AUTOSAR XML (schema 4-0-3)
package /ComponentTypes
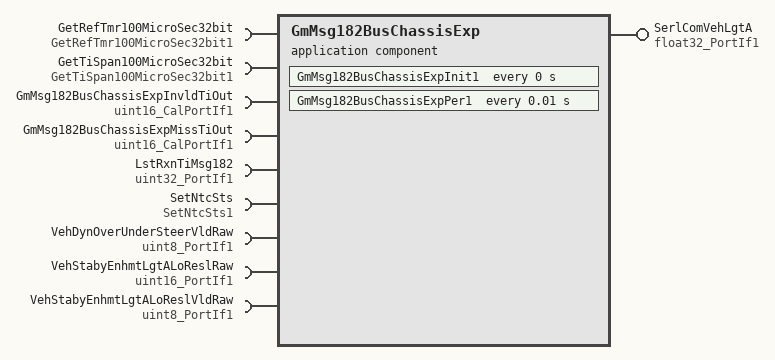
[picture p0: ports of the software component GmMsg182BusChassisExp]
  application sw component type GmMsg182BusChassisExp
    provide port SerlComVehLgtA: nonqueued-sender-com-spec{data-element=Val, init-value=0}, provided-interface=float32_PortIf1
    9 x require port:
      GetRefTmr100MicroSec32bit: required-interface=GetRefTmr100MicroSec32bit1
      GetTiSpan100MicroSec32bit: required-interface=GetTiSpan100MicroSec32bit1
      GmMsg182BusChassisExpInvldTiOut: parameter-require-com-spec{init-value=500, parameter=Val}, required-interface=uint16_CalPortIf1
      GmMsg182BusChassisExpMissTiOut: parameter-require-com-spec{init-value=1000, parameter=Val}, required-interface=uint16_CalPortIf1
      LstRxnTiMsg182: nonqueued-receiver-com-spec{data-element=Val, filter=data-filter-type=ALWAYS, init-value=0}, required-interface=uint32_PortIf1
      SetNtcSts: required-interface=SetNtcSts1
      VehDynOverUnderSteerVldRaw: nonqueued-receiver-com-spec{data-element=Val, filter=data-filter-type=ALWAYS, init-value=0}, required-interface=uint8_PortIf1
      VehStabyEnhmtLgtALoReslRaw: nonqueued-receiver-com-spec{data-element=Val, filter=data-filter-type=ALWAYS, init-value=0}, required-interface=uint16_PortIf1
      VehStabyEnhmtLgtALoReslVldRaw: nonqueued-receiver-com-spec{data-element=Val, filter=data-filter-type=ALWAYS, init-value=0}, required-interface=uint8_PortIf1
    behavior GmMsg182BusChassisExp_InternalBehavior: data-type-mapping=Nexteer
      ar-typed-per-instance-memorys:
        data GmMsg182BusChassisExpInvldTmr: sw-calibration-access=READ-ONLY, type=uint32
        data GmMsg182BusChassisExpPrevVehLgtA: sw-calibration-access=READ-ONLY, type=float32
      timing event GmMsg182BusChassisExp_InitEvent: start-on-event=GmMsg182BusChassisExpInit1, period=0
      timing event TMT_GM0C9HSPer1: start-on-event=GmMsg182BusChassisExpPer1, period=0.01
      runnable GmMsg182BusChassisExpInit1
      runnable GmMsg182BusChassisExpPer1
        data-receive-point-by-arguments:
          4 x access:
            REC_Msg0C9HSLstRxnTi_Val: accessed-variable=LstRxnTiMsg182.Val
            REC_VehDynOverUnderSteerVldRaw_Val: accessed-variable=VehDynOverUnderSteerVldRaw.Val
            REC_VehStabyEnhmtLgtALoReslRaw_Val: accessed-variable=VehStabyEnhmtLgtALoReslRaw.Val
            REC_VehStabyEnhmtLgtALoReslVldRaw_Val: accessed-variable=VehStabyEnhmtLgtALoReslVldRaw.Val
        data-send-points:
          access SEND_SerlComVehLgtA_Val: accessed-variable=SerlComVehLgtA.Val
        sync call SC_GetRefTmr100MicroSec32bit_Oper: operation=GetRefTmr100MicroSec32bit.Oper, timeout=0
        sync call SC_GetTiSpan100MicroSec32bit_Oper: operation=GetTiSpan100MicroSec32bit.Oper, timeout=0
        sync call SC_SetNtcSts_Oper: operation=SetNtcSts.Oper, timeout=0
  swc implementation GmMsg182BusChassisExp_Implementation: behavior=GmMsg182BusChassisExp_InternalBehavior
    code-descriptors:
      code Default: artifact-descriptors=autosar-engineering-object={short-label=Default, category=SWSRC}
